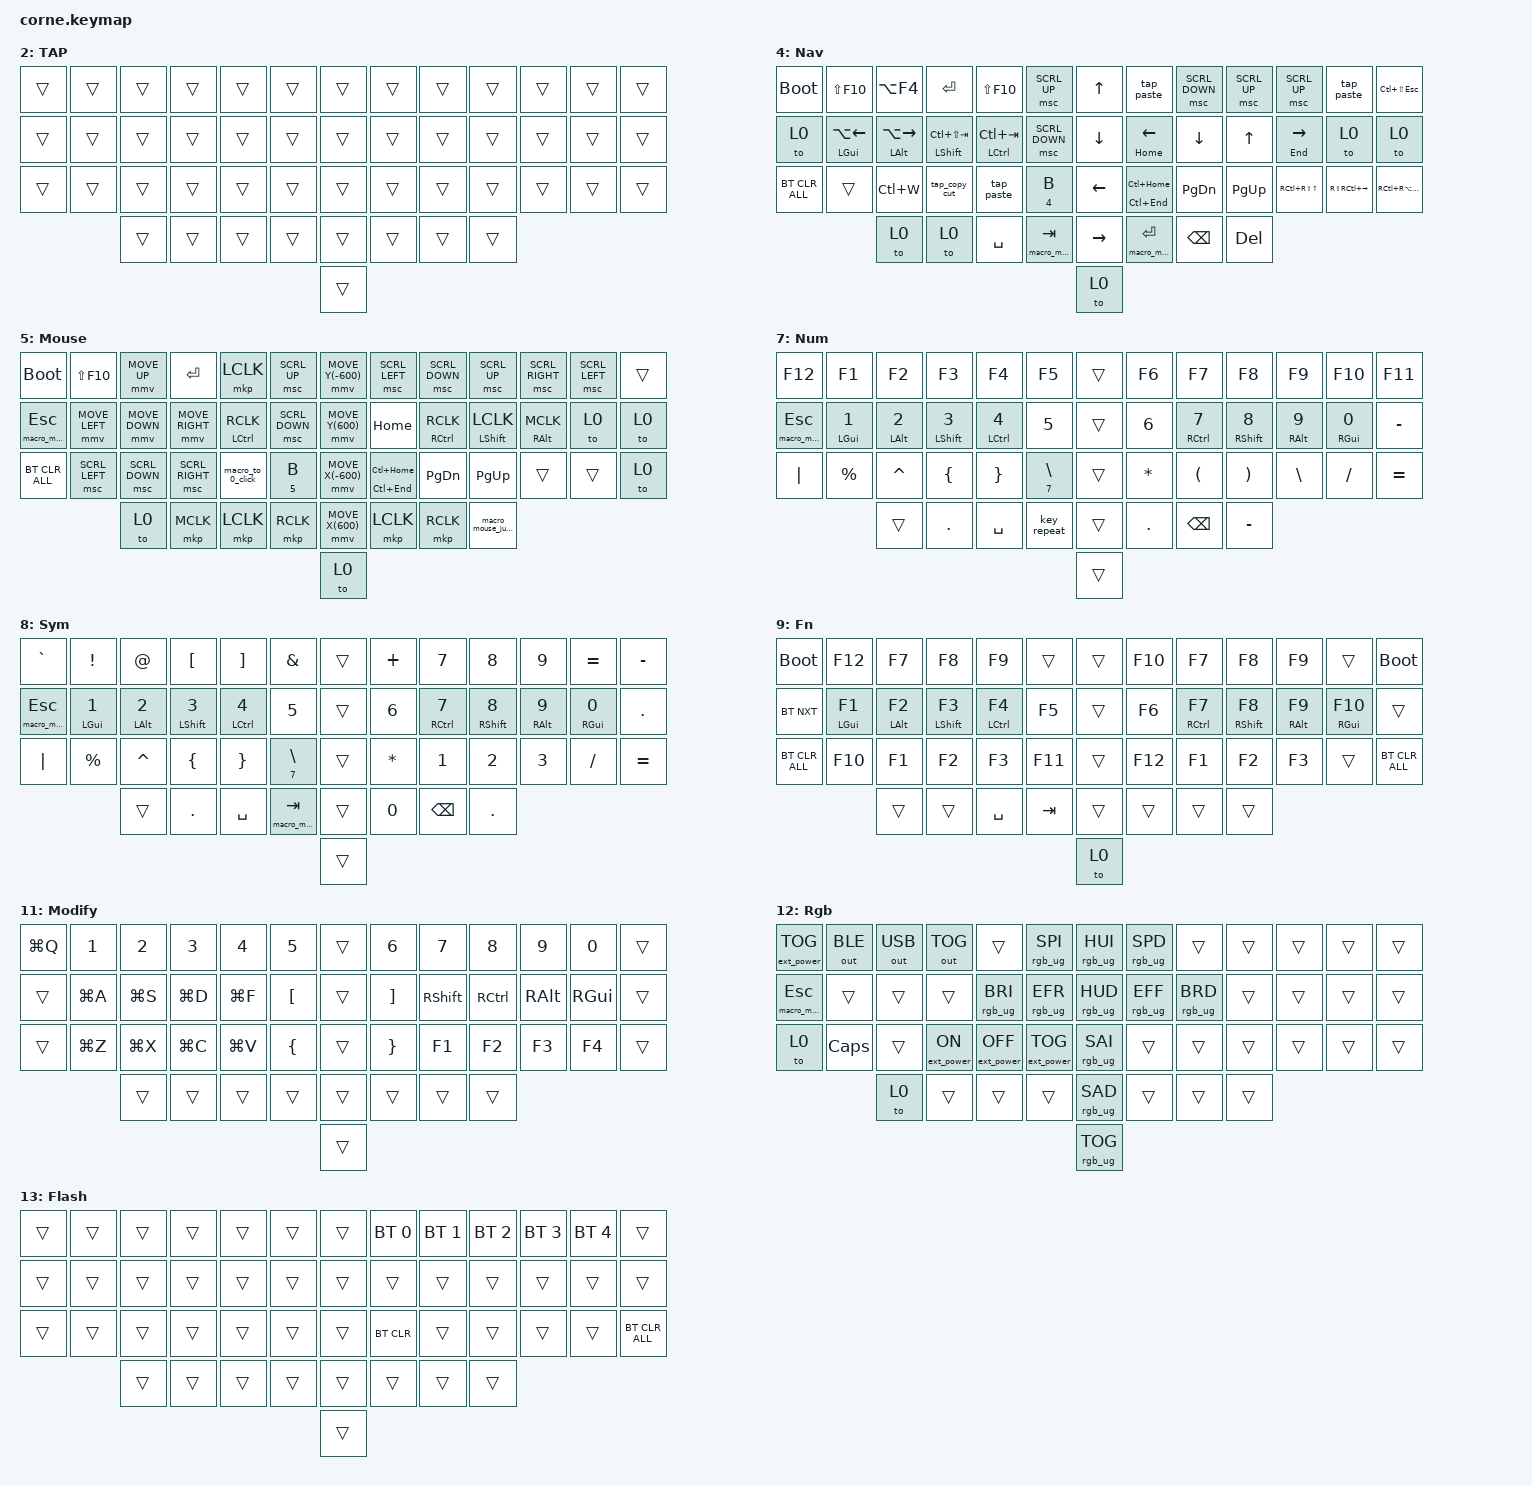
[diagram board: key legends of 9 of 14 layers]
#define ZMK_POINTING_DEFAULT_MOVE_VAL 600  // 600
#define ZMK_POINTING_DEFAULT_SCRL_VAL 10    // 10

#include <behaviors/num_word.dtsi> // Requires auto-layer module.
#include <input/processors.dtsi>
#include <zephyr/dt-bindings/input/input-event-codes.h>
#include "zmk-helpers/helper.h"
#include <behaviors.dtsi>
#include <dt-bindings/zmk/bt.h>
#include <dt-bindings/zmk/ext_power.h>
#include <dt-bindings/zmk/keys.h>
#include <dt-bindings/zmk/outputs.h>
#include <dt-bindings/zmk/pointing.h>
#include <dt-bindings/zmk/rgb.h>


/ {
    zip_scroll_scaler: zip_scroll_scaler {
        compatible = "zmk,input-processor-scaler";
        #input-processor-cells = <2>;
        type = <INPUT_EV_REL>;
        codes = <INPUT_REL_WHEEL INPUT_REL_HWHEEL>;
        track-remainders;
    };
};

&mmv_input_listener { input-processors = <&zip_xy_scaler 2 1>; };

&msc_input_listener { input-processors = <&zip_scroll_scaler 2 1>; };

&msc {
    acceleration-exponent = <0>;      // 0
    time-to-max-speed-ms = <0>;       // 300
    delay-ms = <0>;                   // 0
};

&mmv {
    time-to-max-speed-ms = <300>;
    acceleration-exponent = <1>;
};

&inc_dec_kp {
    tap-ms = <5>;
    bindings = <&kp>, <&kp>;
};

&sk { quick-release; };

&sl {
    ignore-modifiers;          // allow chording sticky mods & layers
};

&lt {
    flavor = "balanced";
    tapping-term-ms = <200>;
    quick-tap-ms = <175>;
};

/ {
    macros {
        macro_dot_shift: macro_dot_shift {
            compatible = "zmk,behavior-macro";
            #binding-cells = <0>;
            bindings = <&kp DOT &kp SPACE &sk LSHFT>;
            label = "MACRO_DOT_SHIFT";
        };

        macro_mouse_jump: to_mouse {
            compatible = "zmk,behavior-macro";
            #binding-cells = <0>;
            bindings = <&kp LS(RG(D)) &to 5>;
            label = "TO_MOUSE";
        };

        macro_to_0_click: macro_to_0_click {
            compatible = "zmk,behavior-macro";
            #binding-cells = <0>;
            bindings = <&mkp RCLK &to 0>;
            label = "MACRO_TO_0_CLICK";
        };

        macro_sel_word: macro_sel_word {
            compatible = "zmk,behavior-macro";
            #binding-cells = <0>;
            bindings = <&kp LC(LEFT) &kp LC(LS(RIGHT))>;
            label = "MACRO_SEL_WORD";
        };

        macro_sel_line: macro_sel_line {
            compatible = "zmk,behavior-macro";
            #binding-cells = <0>;
            bindings = <&kp HOME &kp LS(END)>;
            label = "MACRO_SEL_LINE";
        };

        macro_win_sleep: macro_win_sleep {
            compatible = "zmk,behavior-macro";
            #binding-cells = <0>;
            bindings = <&kp LG(X) &kp U &kp S>;
            label = "MACRO_WIN_SLEEP";
            wait-ms = <500>;
            tap-ms = <5>;
        };

        macro_swapper: macro_swapper {
            compatible = "zmk,behavior-macro";
            #binding-cells = <0>;
            bindings =
                <&macro_press>,
                <&kp LALT>,
                <&macro_tap>,
                <&kp TAB>,
                <&macro_release>,
                <&kp LALT>;

            label = "MACRO_SWAPPER";
        };

        double_click: double_click {
            compatible = "zmk,behavior-macro";
            #binding-cells = <0>;
            bindings = <&mkp RCLK &mkp RCLK>;
            label = "DOUBLE_CLICK";
        };

        macro_mouse_jiggle: mouse_jiggle {
            compatible = "zmk,behavior-macro";
            #binding-cells = <0>;
            bindings = <&to 0 &mmv MOVE_UP &mmv MOVE_LEFT &mmv MOVE_DOWN &mmv MOVE_RIGHT>;
            label = "MOUSE_JIGGLE";
        };

        macro_copy_path: macro_copy_path {
            compatible = "zmk,behavior-macro";
            #binding-cells = <0>;
            bindings = <&kp LC(L) &kp LC(C) &kp ESC>;
            label = "MACRO_COPY_PATH";
        };
    };

    behaviors {
        hml: homerow_mods_left {
            compatible = "zmk,behavior-hold-tap";
            label = "HOMEROW_MODS_LEFT";
            bindings = <&kp>, <&kp>;

            #binding-cells = <2>;
            tapping-term-ms = <175>;
            quick-tap-ms = <150>;
            flavor = "balanced";
            require-prior-idle-ms = <0>;
            hold-trigger-key-positions = <21 22 23 41 20 7 8 33 34 35 36 37 38 25 24 11 12 10 9 44 45 46 14 40 42>;
        };

        hmr: homerow_mods_right {
            compatible = "zmk,behavior-hold-tap";
            label = "HOMEROW_MODS_RIGHT";
            bindings = <&kp>, <&kp>;

            #binding-cells = <2>;
            tapping-term-ms = <175>;
            quick-tap-ms = <150>;
            flavor = "balanced";
            require-prior-idle-ms = <0>;
            hold-trigger-key-positions = <14 15 16 17 0 1 13 26 27 28 29 30 31 5 2 3 4 18 23 45 46 44>;
        };

        ltq: ltq {
            compatible = "zmk,behavior-hold-tap";
            label = "LTQ";
            bindings = <&mo>, <&kp>;

            #binding-cells = <2>;
            tapping-term-ms = <175>;
            quick-tap-ms = <150>;
            flavor = "balanced";
            require-prior-idle-ms = <50>;
            hold-trigger-key-positions = <21 22 23 24 2 15 16 1>;
        };

        as: auto_shift {
            compatible = "zmk,behavior-hold-tap";
            label = "AUTO_SHIFT";
            bindings = <&kp>, <&kp>;

            #binding-cells = <2>;
            tapping-term-ms = <225>;
            quick-tap-ms = <175>;
            flavor = "tap-preferred";
            require-prior-idle-ms = <50>;
        };

        num_word: num_word {
            compatible = "zmk,behavior-auto-layer";
            #binding-cells = <1>;
            continue-list = <BSPC DEL KP_DOT DOT COMMA KP_PLUS PLUS KP_MINUS MINUS KP_MULTIPLY STAR KP_DIVIDE FSLH EQUAL>;
            ignore-numbers;
        };

        smart_num: smart_num {
            compatible = "zmk,behavior-hold-tap";
            label = "SMART_NUM";
            bindings = <&mo>, <&num_word>;

            #binding-cells = <2>;
            tapping-term-ms = <175>;
            flavor = "balanced";
            hold-trigger-key-positions = <41>;
            quick-tap-ms = <150>;
            hold-while-undecided;
        };

        rgb_encoder: rgb_encoder {
            compatible = "zmk,behavior-sensor-rotate";
            label = "RGB_ENCODER";
            #sensor-binding-cells = <0>;
            bindings = <&rgb_ug RGB_BRI>, <&rgb_ug RGB_BRD>;

            tap-ms = <5>;
        };

        scroll_encoder: scroll_encoder {
            compatible = "zmk,behavior-sensor-rotate";
            #sensor-binding-cells = <0>;
            bindings = <&msc SCRL_UP>, <&msc SCRL_DOWN>;

            tap-ms = <5>;
            label = "scroll_encoder";
        };

        backspace_delete: backspace_delete {
            compatible = "zmk,behavior-mod-morph";
            #binding-cells = <0>;
            bindings = <&kp BACKSPACE>, <&kp DELETE>;

            mods = <(MOD_LSFT|MOD_RSFT)>;
            keep-mods = <(MOD_RSFT)>;
            label = "BACKSPACE_DELETE";
        };

        tap_dot_shift: tap_dot_shift {
            compatible = "zmk,behavior-tap-dance";
            label = "tap_dot_shift";
            #binding-cells = <0>;
            bindings = <&kp DOT>, <&macro_dot_shift>;

            tapping-term-ms = <250>;
        };

        sk_qr: sk_qr {
            compatible = "zmk,behavior-sticky-key";
            label = "SK_QR";
            bindings = <&sk>;
            #binding-cells = <1>;
            quick-release;
            release-after-ms = <900>;
        };

        morph_column: morph_column {
            compatible = "zmk,behavior-mod-morph";
            label = "MORPH_COLUMN";
            bindings = <&kp COLON>, <&kp SEMI>;

            #binding-cells = <0>;
            mods = <(MOD_LSFT|MOD_RSFT)>;
            keep-mods = <(MOD_LSFT|MOD_RSFT)>;
        };

        ltq_mouse_column: ltq_mouse_column {
            compatible = "zmk,behavior-hold-tap";
            label = "LTQ_MOUSE_COLUMN";
            bindings = <&mo>, <&morph_column>;

            #binding-cells = <2>;
            flavor = "balanced";
            tapping-term-ms = <175>;
            quick-tap-ms = <150>;
            require-prior-idle-ms = <50>;
            hold-trigger-key-positions = <15 14 2 16 4 17 41 42 44 45 20>;
        };

        tap_quote_to_nav_mouse: tap_quote_to_nav_mouse {
            compatible = "zmk,behavior-tap-dance";
            label = "TAP_QUOTE_TO_NAV_MOUSE";
            #binding-cells = <0>;
            bindings = <&kp SQT>, <&to 4>, <&to 5>;

            tapping-term-ms = <150>;
        };

        mo_dot_shift: mo_dot_shift {
            compatible = "zmk,behavior-hold-tap";
            label = "MO_DOT_SHIFT";
            bindings = <&macro_dot_shift>, <&kp>;

            #binding-cells = <2>;
            tapping-term-ms = <250>;
            quick-tap-ms = <200>;
            flavor = "tap-preferred";
            require-prior-idle-ms = <150>;
            hold-trigger-on-release;
        };

        hmr_clk: hmr_clk {
            compatible = "zmk,behavior-hold-tap";
            label = "HMR_CLK";
            bindings = <&hmr>, <&mkp>;

            #binding-cells = <2>;
            tapping-term-ms = <250>;
            quick-tap-ms = <200>;
            flavor = "tap-preferred";
            require-prior-idle-ms = <150>;
        };

        v_tap_paste: v_tap_paste {
            compatible = "zmk,behavior-tap-dance";
            label = "V_TAP_PASTE";
            #binding-cells = <0>;
            tapping-term-ms = <250>;
            bindings = <&kp V>, <&kp LC(V)>, <&kp LC(LS(V))>;
        };

        tap_paste: tap_paste {
            compatible = "zmk,behavior-tap-dance";
            label = "TAP_PASTE";
            #binding-cells = <0>;
            tapping-term-ms = <250>;
            bindings = <&kp LC(V)>, <&kp LC(LS(V))>;
        };

        tap_copy_cut: tap_copy_cut {
            compatible = "zmk,behavior-tap-dance";
            label = "TAP_COPY_CUT";
            #binding-cells = <0>;
            tapping-term-ms = <250>;
            bindings = <&kp LC(C)>, <&kp LC(X)>;
        };

        tap_dot_shift_capsword: tap_dot_shift_capsword {
            compatible = "zmk,behavior-tap-dance";
            label = "TAP_DOT_SHIFT_CAPSWORD";
            #binding-cells = <0>;
            tapping-term-ms = <250>;
            bindings = <&as_dot_shift 0 DOT>, <&macro_dot_shift>, <&caps_word>;
        };

        tap_key_repeat_ltq: tap_key_repeat_ltq {
            compatible = "zmk,behavior-hold-tap";
            label = "TAP_KEY_REPEAT_LTQ";
            #binding-cells = <2>;
            tapping-term-ms = <225>;
            quick-tap-ms = <175>;
            flavor = "balanced";
            require-prior-idle-ms = <50>;
            bindings = <&mo>, <&key_repeat>;
        };

        kp_to: kp_to {
            compatible = "zmk,behavior-hold-tap";
            label = "KP_TO";
            bindings = <&to>, <&kp>;

            #binding-cells = <2>;
            tapping-term-ms = <175>;
            quick-tap-ms = <175>;
            flavor = "balanced";
            require-prior-idle-ms = <50>;
        };

        mod_to0_mouse_jiggle: mod_to0_mouse_jiggle {
            compatible = "zmk,behavior-hold-tap";
            label = "MOD_TO0_MOUSE_JIGGLE";
            bindings = <&macro_mouse_jiggle>, <&kp>;

            #binding-cells = <2>;
            tapping-term-ms = <225>;
            quick-tap-ms = <175>;
            flavor = "tap-preferred";
            require-prior-idle-ms = <50>;
        };

        tap_flip_komorebic: tap_flip_komorebic {
            compatible = "zmk,behavior-tap-dance";
            label = "TAP_FLIP_KOMOREBIC";
            #binding-cells = <0>;
            tapping-term-ms = <200>;
            bindings = <&kp RS(RA(F17))>, <&kp RA(RS(F18))>, <&none>;
        };

        tap_key_repeat_to: tap_key_repeat_to {
            compatible = "zmk,behavior-hold-tap";
            label = "TAP_KEY_REPEAT_TO";
            bindings = <&to>, <&key_repeat>;

            #binding-cells = <2>;
            tapping-term-ms = <225>;
            quick-tap-ms = <175>;
            flavor = "balanced";
            require-prior-idle-ms = <50>;
        };

        macro_dot_shift_ltq: macro_dot_shift_ltq {
            compatible = "zmk,behavior-hold-tap";
            label = "MACRO_DOT_SHIFT_LTQ";
            #binding-cells = <2>;
            tapping-term-ms = <225>;
            quick-tap-ms = <175>;
            flavor = "balanced";
            require-prior-idle-ms = <50>;
            bindings = <&ltq>, <&macro_dot_shift>;
        };

        shift_mod: shift_mod {
            compatible = "zmk,behavior-hold-tap";
            label = "SHIFT_MOD";
            bindings = <&kp>, <&kp>;

            #binding-cells = <2>;
            tapping-term-ms = <125>;
            quick-tap-ms = <150>;
            flavor = "balanced";
            require-prior-idle-ms = <0>;
            hold-trigger-key-positions = <14 15 16 17 0 1 13 26 27 28 29 31 5 2 3 4 18 23 45 46 44 30 33 20 7 8 21 34 22 9 35 36 37 38 25 24 11 12 10 41 42 40 39 19 32 47 43 6>;
        };

        as_dot_shift: as_dot_shift {
            compatible = "zmk,behavior-hold-tap";
            label = "AS_DOT_SHIFT";
            bindings = <&mo_dot_shift>, <&kp>;

            #binding-cells = <2>;
            tapping-term-ms = <175>;
            flavor = "balanced";
        };

        tap_key_repeat_sk_shift: tap_key_repeat_sk_shift {
            compatible = "zmk,behavior-hold-tap";
            label = "TAP_KEY_REPEAT_SK_SHIFT";
            #binding-cells = <2>;
            tapping-term-ms = <150>;
            quick-tap-ms = <150>;
            flavor = "balanced";
            require-prior-idle-ms = <50>;
            bindings = <&sk>, <&key_repeat>;

            hold-trigger-key-positions = <0 1 14 27 2 3 4 5 15 16 17 18 28 29 30 31 6 19 43 47 32 7 8 9 10 11 12 20 21 22 23 24 25 33 34 35 36 37 38>;
        };

        sk_shift_dot_shift: sk_shift_dot_shift {
            compatible = "zmk,behavior-hold-tap";
            label = "SK_SHIFT_DOT_SHIFT";
            bindings = <&macro_dot_shift>, <&sk>;

            #binding-cells = <2>;
            tapping-term-ms = <250>;
            flavor = "tap-preferred";
            quick-tap-ms = <200>;
        };

        mo_num_word: mo_num_word {
            compatible = "zmk,behavior-hold-tap";
            label = "MO_NUM_WORD";
            bindings = <&num_word>, <&kp>;

            #binding-cells = <2>;
            tapping-term-ms = <175>;
            flavor = "tap-preferred";
            quick-tap-ms = <150>;
        };

        mouse_word: mouse_word {
            compatible = "zmk,behavior-auto-layer";
            #binding-cells = <1>;
            continue-list = <PG_DN PG_UP SCRL_LEFT SCRL_RIGHT SCRL_DOWN SCRL_UP LCLK RCLK MCLK MOVE_LEFT MOVE_RIGHT MOVE_UP MOVE_DOWN>;
            ignore-numbers;
            label = "MOUSE_WORD";
        };

        morph_column_mouse_word: morph_column_mouse_word {
            compatible = "zmk,behavior-hold-tap";
            label = "MORPH_COLUMN_MOUSE_WORD";
            bindings = <&mouse_word>, <&morph_column>;

            #binding-cells = <2>;
            flavor = "balanced";
            tapping-term-ms = <175>;
            quick-tap-ms = <150>;
        };

        nav_word: nav_word {
            compatible = "zmk,behavior-auto-layer";
            #binding-cells = <1>;
            continue-list = <SCRL_LEFT SCRL_RIGHT SCRL_DOWN SCRL_UP LCLK RCLK MCLK MOVE_LEFT MOVE_RIGHT MOVE_UP MOVE_DOWN LEFT DOWN UP RIGHT PG_DN PG_UP HOME END ENTER BACKSPACE DEL>;
            ignore-numbers;
            label = "NAV_WORD";
        };

        wm_word: wm_word {
            compatible = "zmk,behavior-auto-layer";
            #binding-cells = <1>;
            continue-list = <F13 F14 F15 F22 F17 F18 F19 F20 F21 F22>;
            ignore-numbers;
            label = "WM_WORD";
        };

        tap_key_repeat_wm_word: tap_key_repeat_wm_word {
            compatible = "zmk,behavior-hold-tap";
            label = "TAP_KEY_REPEAT_WM_WORD";
            bindings = <&wm_word>, <&key_repeat>;

            #binding-cells = <2>;
            tapping-term-ms = <175>;
            quick-tap-ms = <150>;
            require-prior-idle-ms = <150>;
            flavor = "tap-preferred";
        };

        mo_nav_word: mo_nav_word {
            compatible = "zmk,behavior-hold-tap";
            label = "MO_NAV_WORD";
            bindings = <&nav_word>, <&kp>;

            #binding-cells = <2>;
            flavor = "balanced";
            tapping-term-ms = <175>;
            quick-tap-ms = <150>;
        };

        ltq_num_word: ltq_num_word {
            compatible = "zmk,behavior-hold-tap";
            label = "LTQ_NUM_WORD";
            bindings = <&mo>, <&num_word>;

            #binding-cells = <2>;
            tapping-term-ms = <175>;
            flavor = "tap-preferred";
            quick-tap-ms = <150>;
        };

        ltq_nav_word: ltq_nav_word {
            compatible = "zmk,behavior-hold-tap";
            label = "LTQ_NAV_WORD";
            bindings = <&mo>, <&nav_word>;

            #binding-cells = <2>;
            tapping-term-ms = <175>;
            flavor = "tap-preferred";
            quick-tap-ms = <150>;
        };

        kp_msc: kp_msc {
            compatible = "zmk,behavior-hold-tap";
            label = "KP_MSC";
            bindings = <&msc>, <&kp>;

            #binding-cells = <2>;
            tapping-term-ms = <175>;
            flavor = "balanced";
            quick-tap-ms = <150>;
            hold-trigger-key-positions = <21 22 23 24 45>;
            require-prior-idle-ms = <150>;
        };

        tap_repeat_mouse_word: tap_repeat_mouse_word {
            compatible = "zmk,behavior-hold-tap";
            label = "TAP_REPEAT_MOUSE_WORD";
            bindings = <&mouse_word>, <&key_repeat>;

            #binding-cells = <2>;
            tapping-term-ms = <175>;
            quick-tap-ms = <150>;
            require-prior-idle-ms = <150>;
            flavor = "tap-preferred";
        };

        tap_sk_shift_dot_caps_word_ltq: tap_sk_shift_dot_caps_word_ltq {
            compatible = "zmk,behavior-tap-dance";
            label = "TAP_SK_SHIFT_DOT_CAPS_WORD_LTQ";
            #binding-cells = <0>;
            bindings = <&sk LSHIFT>, <&macro_dot_shift>, <&caps_word>;

            tapping-term-ms = <350>;
        };

        smart_sk_ltq: smart_sk_ltq {
            compatible = "zmk,behavior-hold-tap";
            label = "SMART_SK_LTQ";
            bindings = <&ltq>, <&tap_sk_shift_dot_caps_word_ltq>;

            #binding-cells = <2>;
            tapping-term-ms = <500>;
            quick-tap-ms = <450>;
            flavor = "balanced";
            hold-trigger-key-positions = <0 1 2 3 4 5 7 8 9 10 11 12 13 14 15 16 17 18 19 20 21 22 23 24 25 26 27 28 29 30 31 32 33 34 35 36 37 38 39 40 41 42 43 44 45 46 47 6>;
        };
    };
};


/ {
    combos {
        compatible = "zmk,combos";

        tap_copy_cut {
            bindings = <&tap_copy_cut>;
            key-positions = <28 29>;
        };

        tap_paste {
            bindings = <&tap_paste>;
            key-positions = <29 30>;
        };

        Undo_rh {
            bindings = <&kp LC(Z)>;
            key-positions = <35 34>;
        };

        Redo_rh {
            bindings = <&kp LS(LC(Z))>;
            key-positions = <6 19>;
        };

        Flow_launcher_v1 {
            bindings = <&kp LC(LS(LA(LG(SPACE))))>;
            key-positions = <41 17>;
            timeout-ms = <50>;
            require-prior-idle-ms = <50>;
        };

        to_mouse {
            bindings = <&to 5>;
            key-positions = <24 23>;
        };

        macro_dot_shift_v1 {
            bindings = <&macro_dot_shift>;
            key-positions = <41 16>;
            layers = <0>;
        };

        Select_all {
            bindings = <&kp LC(A)>;
            key-positions = <17 14>;
            layers = <0>;
            slow-release;
        };

        Undo_lh {
            bindings = <&kp LC(Z)>;
            key-positions = <27 28>;
        };

        Redo_lh {
            bindings = <&kp LS(LC(Z))>;
            key-positions = <26 27>;
        };

        Esc_rh {
            bindings = <&kp ESC>;
            key-positions = <8 7>;
            slow-release;
        };

        f21 {
            bindings = <&kp F21>;
            key-positions = <42 44>;
            timeout-ms = <30>;
            require-prior-idle-ms = <30>;
        };

        Down_v2 {
            bindings = <&kp DOWN>;
            key-positions = <41 21>;
        };

        Up_v2 {
            bindings = <&kp UP>;
            key-positions = <41 22>;
        };

        Left {
            bindings = <&kp LEFT>;
            key-positions = <20 41>;
        };

        Right {
            bindings = <&kp RIGHT>;
            key-positions = <23 41>;
        };

        Macro_dot_shift_v2 {
            bindings = <&macro_dot_shift>;
            key-positions = <41 44>;
            layers = <0>;
        };

        Enter_lh {
            bindings = <&kp RET>;
            key-positions = <16 29>;
            slow-release;
        };

        Flow_launcher_rh {
            bindings = <&kp LS(LG(LA(LC(SPACE))))>;
            key-positions = <21 45>;
            timeout-ms = <50>;
            require-prior-idle-ms = <50>;
        };

        Enter_rh {
            bindings = <&kp RET>;
            key-positions = <22 35>;
            slow-release;
        };

        macro_dot_shift_v3 {
            bindings = <&macro_dot_shift>;
            key-positions = <14 15>;
            layers = <0>;
        };

        tab_lh {
            bindings = <&kp TAB>;
            key-positions = <17 30>;
            timeout-ms = <50>;
            require-prior-idle-ms = <75>;
        };

        tab_rh {
            bindings = <&kp TAB>;
            key-positions = <21 34>;
            timeout-ms = <50>;
            require-prior-idle-ms = <75>;
        };

        Enter_rhv2 {
            bindings = <&kp RET>;
            key-positions = <44 45>;
        };

        Ent_lhv2 {
            bindings = <&kp RET>;
            key-positions = <16 3>;
            slow-release;
        };

        Ent_rhv2 {
            bindings = <&kp RET>;
            key-positions = <9 22>;
            slow-release;
        };

        TAB_lhv3 {
            bindings = <&kp TAB>;
            key-positions = <17 4>;
            timeout-ms = <50>;
            require-prior-idle-ms = <75>;
        };

        TAB_rhv3 {
            bindings = <&kp TAB>;
            key-positions = <21 8>;
            timeout-ms = <50>;
            require-prior-idle-ms = <75>;
        };

        t0_mouse_jiggle {
            bindings = <&macro_mouse_jiggle>;
            key-positions = <0 13>;
        };

        SCRL_UP_lh {
            bindings = <&msc SCRL_UP>;
            key-positions = <5 18>;
        };

        SCRL_DOWN_lh {
            bindings = <&msc SCRL_DOWN>;
            key-positions = <18 31>;
        };
    };

    #define KEYS_L LT0 LT1 LT2 LT3 LT4 LT5 LM0 LM1 LM2 LM3 LM4 LM5 LB0 LB1 LB2 LB3 LB4 LB5  // left hand
#define KEYS_R RT0 RT1 RT2 RT3 RT4 RT5 RM0 RM1 RM2 RM3 RM4 RM5 RB0 RB1 RB2 RB3 RB4 RB5  // right hand
#define THUMBS LH2 LH1 LH0 RH0 RH1 RH2   // thumbs
 
    keymap {
        compatible = "zmk,keymap";

        BASE {
            bindings = <
&ltq 12 GRAVE                   &as LS(F10) Q  &kp W            &as END E          &as LC(LS(Z)) R      &kp T                       &kp UP_ARROW    &kp Y              &as RC(Z) U       &kp I              &kp O                    &kp P     &as RC(RS(ESC)) MINUS
&mod_to0_mouse_jiggle 0 ESCAPE  &ltq 10 A      &hml LEFT_ALT S  &hml LEFT_SHIFT D  &hml LCTRL F         &hml LGUI G                 &kp DOWN_ARROW  &as HOME H         &hmr RCTRL J      &hmr LEFT_SHIFT K  &hmr RIGHT_ALT L         &kp SEMI  &tap_quote_to_nav_mouse
&ltq 3 LA(TAB)                  &kp Z          &as DEL X        &kp C              &as LC(LA(LS(V))) V  &as N0 B                    &kp LEFT        &as END N          &as PG_DN M       &as PG_UP COMMA    &tap_dot_shift_capsword  &kp FSLH  &as RC(RA(DEL)) EQUAL
                                               &ltq 6 C_MUTE    &smart_num 7 7     &ltq 4 SPACE         &tap_key_repeat_ltq 10 5    &kp RIGHT       &smart_sk_ltq 6 6  &ltq 7 BACKSPACE  &ltq_nav_word 5 5
                                                                                                                                    &to 5
            >;

            label = "BASE";
            sensor-bindings = <&inc_dec_kp UP DOWN>;
        };

        LEADER {
            bindings = <
&trans  &trans  &trans             &trans  &trans          &trans               &trans  &trans  &trans  &trans          &trans  &trans  &trans
&trans  &to 5   &kp LC(LA(LS(M)))  &to 6   &smart_num 7 7  &trans               &trans  &trans  &trans  &trans          &trans  &trans  &trans
&trans  &trans  &trans             &trans  &trans          &kp LS(LA(LC(B)))    &trans  &trans  &trans  &trans          &trans  &trans  &trans
                &trans             &trans  &to 9           &to 4                &trans  &to 5   &to 6   &smart_num 7 7
                                                                                &trans
            >;

            label = "LEADER";
        };

        TAP {
            bindings = <
&trans  &trans  &trans  &trans  &trans  &trans    &trans  &trans  &trans  &trans  &trans  &trans  &trans
&trans  &trans  &trans  &trans  &trans  &trans    &trans  &trans  &trans  &trans  &trans  &trans  &trans
&trans  &trans  &trans  &trans  &trans  &trans    &trans  &trans  &trans  &trans  &trans  &trans  &trans
                &trans  &trans  &trans  &trans    &trans  &trans  &trans  &trans
                                                  &trans
            >;

            label = "TAP";
        };

        BUTTON {
            bindings = <
&kp CAPS  &kp LS(LG(LC(LA(Q))))  &kp LA(F4)  &kp LG(LC(LA(E)))         &kp LC(F24)              &as N3 LS(LA(LC(LG(T))))          &trans  &trans             &trans              &trans             &trans      &kp LG(LC(LA(P)))    &kp RC(RS(ESCAPE))
&trans    &kp LG(LC(LA(T)))      &kp F24     &kp LS(F24)               &kp LG(LC(LA(F)))        &kp LG(LC(LA(G)))                 &trans  &kp LG(LC(LA(H)))  &kp LG(LEFT_ARROW)  &kp LG(DOWN)       &kp LG(UP)  &kp LG(RIGHT_ARROW)  &trans
&trans    &macro_win_sleep       &trans      &kp LG(LC(LA(C)))         &kp LS(LC(V))            &as N3 LS(LA(LC(LG(B))))          &trans  &trans             &trans              &trans             &trans      &trans               &kp RC(RA(DELETE))
                                 &trans      &as LC(LA(LS(M))) C_PREV  &as C_MUTE C_PLAY_PAUSE  &as LS(LG(LA(LC(F11)))) C_NEXT    &trans  &kp F24            &kp RS(F24)         &kp LG(LC(LA(H)))
                                                                                                                                  &trans
            >;

            label = "BUTTON";
            sensor-bindings = <&inc_dec_kp LC(LS(TAB)) LC(LS(TAB))>;
        };

        NAV {
            bindings = <
&bootloader     &kp LS(F10)         &kp LA(F4)           &kp ENTER                    &kp LS(F10)         &msc SCRL_UP                   &kp UP_ARROW    &tap_paste                   &msc SCRL_DOWN  &msc SCRL_UP  &msc SCRL_UP    &tap_paste         &kp LC(LS(ESC))
&to 0           &hml LGUI LA(LEFT)  &hml LALT LA(RIGHT)  &hml LEFT_SHIFT LC(LS(TAB))  &hml LCTRL LC(TAB)  &msc SCRL_DOWN                 &kp DOWN_ARROW  &as HOME LEFT                &kp DOWN        &kp UP        &as END RIGHT   &to 0              &to 0
&bt BT_CLR_ALL  &trans              &kp LC(W)            &tap_copy_cut                &tap_paste          &as N4 B                       &kp LEFT        &as LC(END) LC(HOME)         &kp PG_DN       &kp PG_UP     &kp RC(RS(UP))  &kp RS(RC(RIGHT))  &kp RC(RA(DEL))
                                    &to 0                &to 0                        &kp SPACE           &mod_to0_mouse_jiggle 0 TAB    &kp RIGHT       &mod_to0_mouse_jiggle 0 RET  &kp BACKSPACE   &kp DEL
                                                                                                                                         &to 0
            >;

            sensor-bindings = <&inc_dec_kp UP_ARROW DOWN_ARROW>;
            label = "Nav";
        };

        Mouse {
            bindings = <
&bootloader                  &kp LS(F10)     &mmv MOVE_UP    &kp RET          &mkp LCLK            &msc SCRL_UP      &mmv MOVE_Y(-600)  &msc SCRL_LEFT        &msc SCRL_DOWN       &msc SCRL_UP         &msc SCRL_RIGHT     &msc SCRL_LEFT  &trans
&mod_to0_mouse_jiggle 0 ESC  &mmv MOVE_LEFT  &mmv MOVE_DOWN  &mmv MOVE_RIGHT  &hmr_clk LCTRL RCLK  &msc SCRL_DOWN    &mmv MOVE_Y(600)   &kp HOME              &hmr_clk RCTRL RCLK  &hmr_clk LSHFT LCLK  &hmr_clk RALT MCLK  &to 0           &to 0
&bt BT_CLR_ALL               &msc SCRL_LEFT  &msc SCRL_DOWN  &msc SCRL_RIGHT  &macro_to_0_click    &as N5 B          &mmv MOVE_X(-600)  &as LC(END) LC(HOME)  &kp PG_DN            &kp PG_UP            &trans              &trans          &to 0
                                             &to 0           &mkp MCLK        &mkp LCLK            &mkp RCLK         &mmv MOVE_X(600)   &mkp LCLK             &mkp RCLK            &macro_mouse_jump
                                                                                                                     &to 0
            >;

            label = "Mouse";
            sensor-bindings = <&inc_dec_kp UP_ARROW DOWN_ARROW>;
        };

        SWAP {
            bindings = <
&bootloader                  &trans                &kp LA(F4)            &trans                  &bt BT_PRV            &bt BT_NXT                        &kp LC(W)        &kp LG(LC(LA(N1)))  &kp LG(LC(LA(N2)))  &kp LG(LC(LA(N3)))              &kp LG(LC(LA(N4)))  &kp LG(LC(LA(N5)))  &bootloader
&mod_to0_mouse_jiggle 0 ESC  &kp LC(LG(NUMBER_1))  &kp LC(LG(NUMBER_2))  &kp LC(LG(NUMBER_3))    &kp LC(LG(NUMBER_4))  &kp LC(LG(N5))                    &kp LC(LS(T))    &kp LC(LG(N6))      &kp LC(LG(N7))      &kp LG(LC(N8))                  &kp LC(LG(N9))      &kp LC(LG(N0))      &soft_off
&bt BT_CLR_ALL               &kp LC(LG(N0))        &kp LC(LG(N9))        &kp LC(LG(N8))          &bt BT_PRV            &bt BT_NXT                        &kp LC(LS(TAB))  &bt BT_SEL 0        &bt BT_SEL 1        &bt BT_SEL 2                    &bt BT_SEL 3        &bt BT_SEL 4        &bt BT_CLR_ALL
                                                   &kp N0                &kp LS(LA(LC(LG(F9))))  &ltq 10 LA(F4)        &mod_to0_mouse_jiggle 0 LA(F4)    &kp LC(TAB)      &as RG(TAB) C_PREV  &as C_MUTE LA(F4)   &as RS(RA(RC(RG(F11)))) C_NEXT
                                                                                                                                                         &to 0
            >;

            label = "Swap";
            sensor-bindings = <&inc_dec_kp C_VOLUME_UP C_VOLUME_DOWN>;
        };

        NUM {
            bindings = <
&kp F12                      &kp F1        &kp F2        &kp F3         &kp F4         &kp F5              &trans  &kp F6     &kp F7                &kp F8                 &kp F9         &kp F10       &kp F11
&mod_to0_mouse_jiggle 0 ESC  &hml LGUI N1  &hml LALT N2  &hml LSHFT N3  &hml LCTRL N4  &kp N5              &trans  &kp N6     &hmr RCTRL N7         &hmr RSHFT N8          &hmr RALT N9   &hmr RGUI N0  &kp MINUS
&kp PIPE                     &kp PRCNT     &kp CARET     &kp LBRC       &kp RBRC       &as N7 BACKSLASH    &trans  &kp ASTRK  &kp LEFT_PARENTHESIS  &kp RIGHT_PARENTHESIS  &kp BACKSLASH  &kp FSLH      &kp EQUAL
                                           &trans        &kp DOT        &kp SPACE      &key_repeat         &trans  &kp DOT    &kp BACKSPACE         &kp MINUS
                                                                                                           &trans
            >;

            label = "Num";
        };

        Symbol {
            bindings = <
&kp GRAVE                    &kp EXCL      &kp AT        &kp LBKT       &kp RBKT       &kp AMPS                       &trans  &kp PLUS   &kp N7         &kp N8         &kp N9        &kp EQUAL     &kp MINUS
&mod_to0_mouse_jiggle 0 ESC  &hml LGUI N1  &hml LALT N2  &hml LSHFT N3  &hml LCTRL N4  &kp N5                         &trans  &kp N6     &hmr RCTRL N7  &hmr RSHFT N8  &hmr RALT N9  &hmr RGUI N0  &kp DOT
&kp PIPE                     &kp PRCNT     &kp CARET     &kp LBRC       &kp RBRC       &as N7 BACKSLASH               &trans  &kp ASTRK  &kp N1         &kp N2         &kp N3        &kp FSLH      &kp EQUAL
                                           &trans        &kp DOT        &kp SPACE      &mod_to0_mouse_jiggle 0 TAB    &trans  &kp N0     &kp BACKSPACE  &kp DOT
                                                                                                                      &trans
            >;

            label = "Sym";
            sensor-bindings = <&inc_dec_kp C_VOLUME_UP C_VOLUME_DOWN>;
        };

        Fn {
            bindings = <
&bootloader     &kp F12       &kp F7        &kp F8         &kp F9         &trans     &trans  &kp F10  &kp F7         &kp F8         &kp F9        &trans         &bootloader
&bt BT_NXT      &hml LGUI F1  &hml LALT F2  &hml LSHFT F3  &hml LCTRL F4  &kp F5     &trans  &kp F6   &hmr RCTRL F7  &hmr RSHFT F8  &hmr RALT F9  &hmr RGUI F10  &trans
&bt BT_CLR_ALL  &kp F10       &kp F1        &kp F2         &kp F3         &kp F11    &trans  &kp F12  &kp F1         &kp F2         &kp F3        &trans         &bt BT_CLR_ALL
                              &trans        &trans         &kp SPACE      &kp TAB    &trans  &trans   &trans         &trans
                                                                                     &to 0
            >;

            label = "Fn";
        };

        L10 {
            bindings = <
&bootloader                  &trans                 &kp LA(F15)          &trans              &kp LC(LA(LS(F20)))  &kp F21                  &kp LA(F15)  &trans   &kp RC(RA(F13))  &kp RC(RA(F14))      &kp RC(RA(F15))  &kp RC(RA(F22))  &kp RC(RS(ESC))
&mod_to0_mouse_jiggle 0 ESC  &hml LEFT_WIN LA(F13)  &hml LALT LA(F14)    &hml LSHFT LC(F13)  &hml LCTRL LC(F22)   &hml LEFT_GUI LG(TAB)    &kp LA(F14)  &kp F13  &hmr RCTRL F14   &hmr RSHFT F15       &hmr RALT F22    &to 0            &trans
&bt BT_CLR_ALL               &bt BT_NXT             &kp LC(LS(LA(F17)))  &trans              &kp LC(LS(V))        &as LS(X) B              &kp LA(F13)  &trans   &kp RS(RA(F17))  &kp RS(RA(F18))      &kp F19          &kp F20          &kp RC(RA(DEL))
                                                    &to 0                &kp F21             &kp F21              &key_repeat              &kp LA(F22)  &to 0    &ltq 6 RA(F4)    &tap_flip_komorebic
                                                                                                                                           &to 0
            >;

            label = "L10";
        };

        Modify {
            bindings = <
&kp LG(Q)  &kp NUMBER_1  &kp NUMBER_2  &kp NUMBER_3  &kp NUMBER_4  &kp NUMBER_5        &trans  &kp NUMBER_6       &kp NUMBER_7     &kp NUMBER_8       &kp NUMBER_9   &kp NUMBER_0   &trans
&trans     &kp LG(A)     &kp LG(S)     &kp LG(D)     &kp LG(F)     &kp LEFT_BRACKET    &trans  &kp RIGHT_BRACKET  &kp RIGHT_SHIFT  &kp RIGHT_CONTROL  &kp RIGHT_ALT  &kp RIGHT_GUI  &trans
&trans     &kp LG(Z)     &kp LG(X)     &kp LG(C)     &kp LG(V)     &kp LEFT_BRACE      &trans  &kp RIGHT_BRACE    &kp F1           &kp F2             &kp F3         &kp F4         &trans
                         &trans        &trans        &trans        &trans              &trans  &trans             &trans           &trans
                                                                                       &trans
            >;

            label = "Modify";
        };

        Rgb {
            bindings = <
&ext_power EP_TOG            &out OUT_BLE  &out OUT_USB  &out OUT_TOG      &trans             &rgb_ug RGB_SPI      &rgb_ug RGB_HUI  &rgb_ug RGB_SPD  &trans           &trans  &trans  &trans  &trans
&mod_to0_mouse_jiggle 0 ESC  &trans        &trans        &trans            &rgb_ug RGB_BRI    &rgb_ug RGB_EFR      &rgb_ug RGB_HUD  &rgb_ug RGB_EFF  &rgb_ug RGB_BRD  &trans  &trans  &trans  &trans
&to 0                        &kp CAPSLOCK  &trans        &ext_power EP_ON  &ext_power EP_OFF  &ext_power EP_TOG    &rgb_ug RGB_SAI  &trans           &trans           &trans  &trans  &trans  &trans
                                           &to 0         &trans            &trans             &trans               &rgb_ug RGB_SAD  &trans           &trans           &trans
                                                                                                                   &rgb_ug RGB_TOG
            >;

            label = "Rgb";
            sensor-bindings = <&rgb_encoder &scroll_encoder>;
        };

        Flash {
            bindings = <
&trans  &trans  &trans  &trans  &trans  &trans    &trans  &bt BT_SEL 0  &bt BT_SEL 1  &bt BT_SEL 2  &bt BT_SEL 3  &bt BT_SEL 4  &trans
&trans  &trans  &trans  &trans  &trans  &trans    &trans  &trans        &trans        &trans        &trans        &trans        &trans
&trans  &trans  &trans  &trans  &trans  &trans    &trans  &bt BT_CLR    &trans        &trans        &trans        &trans        &bt BT_CLR_ALL
                &trans  &trans  &trans  &trans    &trans  &trans        &trans        &trans
                                                  &trans
            >;

            label = "Flash";
        };
    };

    conditional_layers { compatible = "zmk,conditional-layers"; };
};
